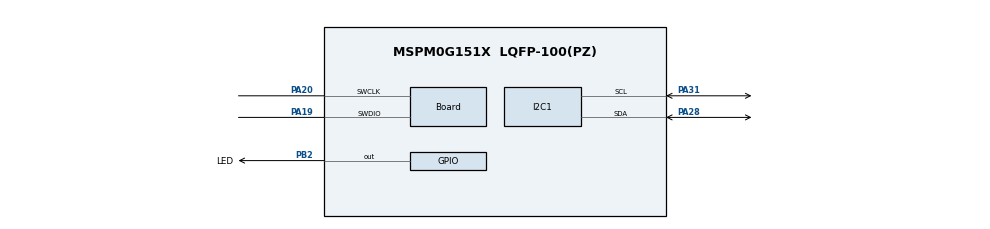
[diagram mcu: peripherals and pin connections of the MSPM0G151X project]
/**
 *
 * @cliArgs --device "MSPM0G151X" --part "Default" --package "LQFP-100(PZ)" --product "mspm0_sdk@2.10.00.04"
 * @versions {"tool":"1.28.0+4712"}
 */
scripting.excludeFromBuild("device_linker.cmd");
scripting.excludeFromBuild("device.opt");
scripting.excludeFromBuild("device.cmd.genlibs");
scripting.excludeFromBuild("device.lds.genlibs");

/**
 * Import the modules used in this configuration.
 */
const Board  = scripting.addModule("/ti/driverlib/Board");
const GPIO   = scripting.addModule("/ti/driverlib/GPIO", {}, false);
const GPIO1  = GPIO.addInstance();
const I2C    = scripting.addModule("/ti/driverlib/I2C", {}, false);
const I2C1   = I2C.addInstance();
const TIMER  = scripting.addModule("/ti/driverlib/TIMER", {}, false);
const TIMER1 = TIMER.addInstance();

/**
 * Write custom configuration values to the imported modules.
 */
const divider7       = system.clockTree["PLL_PDIV"];
divider7.divideValue = 2;

const divider9       = system.clockTree["UDIV"];
divider9.divideValue = 2;

const multiplier2         = system.clockTree["PLL_QDIV"];
multiplier2.multiplyValue = 5;

const mux4       = system.clockTree["EXHFMUX"];
mux4.inputSelect = "EXHFMUX_XTAL";

const mux8       = system.clockTree["HSCLKMUX"];
mux8.inputSelect = "HSCLKMUX_SYSPLL2X";

const pinFunction4       = system.clockTree["HFXT"];
pinFunction4.enable      = true;
pinFunction4.inputFreq   = 16;
pinFunction4.HFXTStartup = 20;

Board.peripheral.$assign          = "DEBUGSS";
Board.peripheral.swclkPin.$assign = "PA20";
Board.peripheral.swdioPin.$assign = "PA19";

GPIO1.$name                         = "LED_GROP";
GPIO1.port                          = "PORTB";
GPIO1.associatedPins[0].$name       = "LED";
GPIO1.associatedPins[0].ioStructure = "SD";
GPIO1.associatedPins[0].assignedPin = "2";
GPIO1.associatedPins[0].pin.$assign = "PB2";

I2C1.$name                     = "I2C_0";
I2C1.basicEnableController     = true;
I2C1.peripheral.sdaPin.$assign = "PA28";
I2C1.peripheral.sclPin.$assign = "PA31";
I2C1.sdaPinConfig.$name        = "ti_driverlib_gpio_GPIOPinGeneric0";
I2C1.sclPinConfig.$name        = "ti_driverlib_gpio_GPIOPinGeneric1";

const SYSCTL              = scripting.addModule("/ti/driverlib/SYSCTL", {}, false);
SYSCTL.peripheral.$assign = "SYSCTL";

TIMER1.$name              = "TIMERBASE";
TIMER1.timerClkDiv        = 8;
TIMER1.peripheral.$assign = "TIMG12";

const ProjectConfig              = scripting.addModule("/ti/project_config/ProjectConfig", {}, false);
ProjectConfig.migrationCondition = true;

/**
 * Pinmux solution for unlocked pins/peripherals. This ensures that minor changes to the automatic solver in a future
 * version of the tool will not impact the pinmux you originally saw.  These lines can be completely deleted in order to
 * re-solve from scratch.
 */
pinFunction4.peripheral.$suggestSolution           = "SYSCTL";
pinFunction4.peripheral.hfxInPin.$suggestSolution  = "PA5";
pinFunction4.peripheral.hfxOutPin.$suggestSolution = "PA6";
I2C1.peripheral.$suggestSolution                   = "I2C0";
